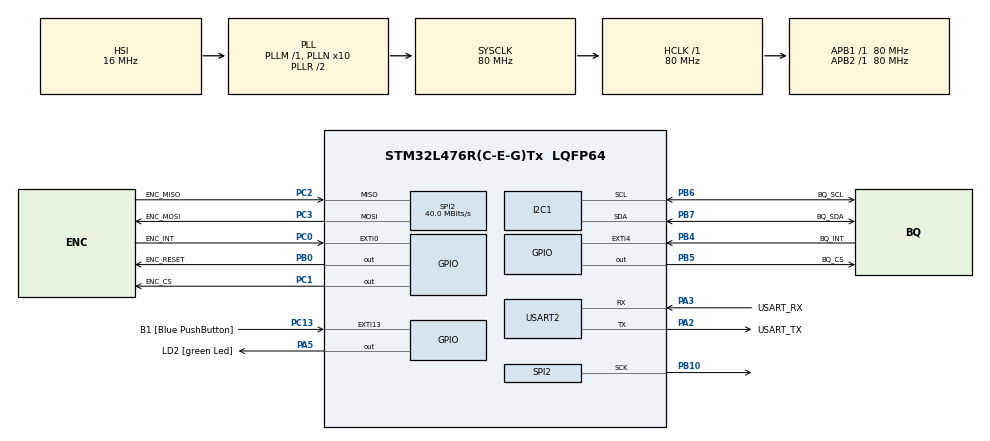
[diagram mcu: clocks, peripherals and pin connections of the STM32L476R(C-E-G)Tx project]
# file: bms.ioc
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FREERTOS.Tasks01=defaultTask,0,128,StartDefaultTask,Default,NULL,Dynamic,NULL,NULL
FREERTOS.configUSE_NEWLIB_REENTRANT=1
I2C1.Timing=0x10909CEC
Mcu.Family=STM32L4
Mcu.Name=STM32L476R(C-E-G)Tx
Mcu.Package=LQFP64
NVIC.EXTI0_IRQn=true\:5\:0\:false\:false\:true\:true\:true\:true\:true
NVIC.EXTI4_IRQn=true\:5\:0\:false\:false\:true\:true\:true\:true\:true
NVIC.PriorityGroup=NVIC_PRIORITYGROUP_4
NVIC.TIM1_UP_TIM16_IRQn=true\:15\:0\:false\:false\:true\:false\:false\:true\:true
NVIC.TimeBase=TIM1_UP_TIM16_IRQn
NVIC.TimeBaseIP=TIM1
PA13\ (JTMS-SWDIO).GPIO_Label=TMS
PA13\ (JTMS-SWDIO).Mode=Serial_Wire
PA13\ (JTMS-SWDIO).Signal=SYS_JTMS-SWDIO
PA14\ (JTCK-SWCLK).GPIO_Label=TCK
PA14\ (JTCK-SWCLK).Mode=Serial_Wire
PA14\ (JTCK-SWCLK).Signal=SYS_JTCK-SWCLK
PA2.GPIO_Label=USART_TX
PA2.GPIO_Mode=GPIO_MODE_AF_PP
PA2.GPIO_PuPd=GPIO_NOPULL
PA2.GPIO_Speed=GPIO_SPEED_FREQ_VERY_HIGH
PA2.Mode=Asynchronous
PA2.Signal=USART2_TX
PA3.GPIO_Label=USART_RX
PA3.GPIO_Mode=GPIO_MODE_AF_PP
PA3.GPIO_PuPd=GPIO_NOPULL
PA3.GPIO_Speed=GPIO_SPEED_FREQ_VERY_HIGH
PA3.Mode=Asynchronous
PA3.Signal=USART2_RX
PA5.GPIO_Label=LD2 [green Led]
PA5.GPIO_ModeDefaultOutputPP=GPIO_MODE_OUTPUT_PP
PA5.GPIO_PuPd=GPIO_NOPULL
PA5.GPIO_Speed=GPIO_SPEED_FREQ_LOW
PA5.Signal=GPIO_Output
PB0.GPIO_Label=ENC_RESET
PB0.GPIO_Speed=GPIO_SPEED_FREQ_VERY_HIGH
PB0.PinState=GPIO_PIN_SET
PB0.Signal=GPIO_Output
PB10.Mode=Full_Duplex_Master
PB10.Signal=SPI2_SCK
PB3\ (JTDO-TRACESWO).GPIO_Label=SWO
PB3\ (JTDO-TRACESWO).Signal=SYS_JTDO-SWO
PB4\ (NJTRST).GPIO_Label=BQ_INT
PB4\ (NJTRST).GPIO_ModeDefaultEXTI=GPIO_MODE_IT_FALLING
PB4\ (NJTRST).Signal=GPXTI4
PB5.GPIO_Label=BQ_CS
PB5.GPIO_Speed=GPIO_SPEED_FREQ_VERY_HIGH
PB5.PinState=GPIO_PIN_SET
PB5.Signal=GPIO_Output
PB6.GPIO_Label=BQ_SCL
PB6.Mode=I2C
PB6.Signal=I2C1_SCL
PB7.GPIO_Label=BQ_SDA
PB7.Mode=I2C
PB7.Signal=I2C1_SDA
PC0.GPIO_Label=ENC_INT
PC0.GPIO_ModeDefaultEXTI=GPIO_MODE_IT_FALLING
PC0.Signal=GPXTI0
PC1.GPIO_Label=ENC_CS
PC1.GPIO_Speed=GPIO_SPEED_FREQ_VERY_HIGH
PC1.PinState=GPIO_PIN_SET
PC1.Signal=GPIO_Output
PC13.GPIO_Label=B1 [Blue PushButton]
PC13.GPIO_ModeDefaultEXTI=GPIO_MODE_IT_FALLING
PC13.GPIO_PuPd=GPIO_NOPULL
PC13.Signal=GPXTI13
PC14-OSC32_IN\ (PC14).Mode=LSE-External-Oscillator
PC14-OSC32_IN\ (PC14).Signal=RCC_OSC32_IN
PC15-OSC32_OUT\ (PC15).Mode=LSE-External-Oscillator
PC15-OSC32_OUT\ (PC15).Signal=RCC_OSC32_OUT
PC2.GPIO_Label=ENC_MISO
PC2.Mode=Full_Duplex_Master
PC2.Signal=SPI2_MISO
PC3.GPIO_Label=ENC_MOSI
PC3.Mode=Full_Duplex_Master
PC3.Signal=SPI2_MOSI
PH0-OSC_IN\ (PH0).Signal=RCC_OSC_IN
PH1-OSC_OUT\ (PH1).Signal=RCC_OSC_OUT
ProjectManager.HeapSize=0x200
ProjectManager.StackSize=0x400
ProjectManager.TargetToolchain=Makefile
RCC.ADCFreq_Value=64000000
RCC.AHBFreq_Value=80000000
RCC.APB1Freq_Value=80000000
RCC.APB1TimFreq_Value=80000000
RCC.APB2Freq_Value=80000000
RCC.APB2TimFreq_Value=80000000
RCC.CortexFreq_Value=80000000
RCC.HCLKFreq_Value=80000000
RCC.HSE_VALUE=8000000
RCC.HSI_VALUE=16000000
RCC.MSI_VALUE=4000000
RCC.PLLN=10
RCC.PLLSourceVirtual=RCC_PLLSOURCE_HSI
RCC.PREFETCH_ENABLE=1
RCC.SYSCLKFreq_VALUE=80000000
RCC.SYSCLKSource=RCC_SYSCLKSOURCE_PLLCLK
RCC.USBFreq_Value=64000000
RCC.VCOOutputFreq_Value=160000000
SPI2.CalculateBaudRate=40.0 MBits/s
SPI2.DataSize=SPI_DATASIZE_8BIT
SPI2.Direction=SPI_DIRECTION_2LINES
SPI2.Mode=SPI_MODE_MASTER
SPI2.VirtualType=VM_MASTER
USART2.VirtualMode-Asynchronous=VM_ASYNC
VP_FREERTOS_VS_CMSIS_V1.Mode=CMSIS_V1
VP_SYS_VS_tim1.Mode=TIM1
board=NUCLEO-L476RG

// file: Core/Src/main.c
/* USER CODE BEGIN Header */
/**
 ******************************************************************************
 * @file           : main.c
 * @brief          : Main program body
 ******************************************************************************
 * @attention
 *
 * Copyright (c) 2022 STMicroelectronics.
 * All rights reserved.
 *
 * This software is licensed under terms that can be found in the LICENSE file
 * in the root directory of this software component.
 * If no LICENSE file comes with this software, it is provided AS-IS.
 *
 ******************************************************************************
 */
/* USER CODE END Header */
#include "main.h"
#include "bq76940.h"
#include "cmsis_os.h"
#include "echoserver.h"
#include "enc28j60.h"
#include "log.h"

I2C_HandleTypeDef hi2c1;

SPI_HandleTypeDef hspi2;

UART_HandleTypeDef huart2;

// TCP Stack - IP configuration
uint8_t ucMACAddress[6] = {0x00, 0x11, 0x00, 0xdd, 0xee, 0xff};
uint8_t ucIPAddress[4] = {172, 16, 15, 133};
uint8_t ucNetMask[4] = {255, 255, 255, 0};
uint8_t ucGatewayAddress[4] = {172, 16, 15, 1};
// The following is the address of an OpenDNS server.
uint8_t ucDNSServerAddress[4] = {208, 67, 222, 222};

void SystemClock_Config(void);
static void MX_GPIO_Init(void);
static void MX_I2C1_Init(void);
static void MX_SPI2_Init(void);
static void MX_USART2_UART_Init(void);

void bq_test() {
  LogDebug("bq_test started\n");

  BQConfig bq_conf = {.scp_threshold = SCD_T_44mV,
                      .scp_delay = SCD_D_100us,
                      .ocp_threshold = OCD_T_17mV,
                      .ocp_delay = OCD_D_8ms,
                      .uv_threshold = 1.5,
                      .uv_delay = UV_D_1s,
                      .ov_threshold = 4.7,
                      .ov_delay = OV_D_1s,
                      .temp_source = TS_SRC_External};

  while (bq769x0_init(&bq_conf)) {
  }
  LogDebug("bq769x0_init success\n");

  LogDebug("cell3: %f\n", bq769x0_read_cell_voltage(BQ_CELL_3));
  LogDebug("pack: %f\n", bq769x0_read_pack_voltage(13));

  while (true) {
    SYS_STAT_Type data = bq769x0_system_faults();
    LogDebug("cell1: %f\n", bq769x0_read_cell_voltage(BQ_CELL_1));
    LogDebug("faults: %d\n", data.byte);
    bq769x0_system_clear_faults(data);
    vTaskDelay(100);
  }

  LogDebug("bq_test stop\n");
  vTaskDelete(NULL);
}

int main(void) {

  HAL_Init();
  SystemClock_Config();
  MX_GPIO_Init();
  MX_I2C1_Init();
  MX_SPI2_Init();
  MX_USART2_UART_Init();

  xLoggingTaskInitialize(1024, 1, 1024);

  LogDebug("CPU, GPIO initialized\n");

  // FreeRTOS_IPInit(ucIPAddress, ucNetMask, ucGatewayAddress,
  // ucDNSServerAddress,
  //                 ucMACAddress);

  xTaskCreate(bq_test, "bq_test", 1024, NULL, osPriorityNormal, NULL);

  LogDebug("starting scheduler\n");
  vTaskStartScheduler();

  /* We should never get here as control is now taken by the scheduler */
  Error_Handler();
}

void vApplicationIPNetworkEventHook(eIPCallbackEvent_t eNetworkEvent) {
  uint32_t ulIPAddress, ulNetMask, ulGatewayAddress, ulDNSServerAddress;
  static BaseType_t xTasksAlreadyCreated = pdFALSE;
  char cBuffer[16];

  /* Both eNetworkUp and eNetworkDown events can be processed here. */
  if (eNetworkEvent == eNetworkUp) {
    LogInfo("Link Up");
    /* Create the tasks that use the TCP/IP stack if they have not already
    been created. */
    if (xTasksAlreadyCreated == pdFALSE) {
      /* Create the task(s) */

      xTaskCreate(vStartSimpleEchoServer, "echo_server", 1024, NULL,
                  osPriorityNormal, NULL);

      xTasksAlreadyCreated = pdTRUE;
    }
    /* The network is up and configured.  Print out the configuration,
   which may have been obtained from a DHCP server. */
    FreeRTOS_GetAddressConfiguration(&ulIPAddress, &ulNetMask,
                                     &ulGatewayAddress, &ulDNSServerAddress);

    /* Convert the IP address to a string then print it out. */
    FreeRTOS_inet_ntoa(ulIPAddress, cBuffer);
    LogInfo("IP Address: %s", cBuffer);

    /* Convert the net mask to a string then print it out. */
    FreeRTOS_inet_ntoa(ulNetMask, cBuffer);
    LogInfo("Subnet Mask: %s", cBuffer);

    /* Convert the IP address of the gateway to a string then print it out. */
    FreeRTOS_inet_ntoa(ulGatewayAddress, cBuffer);
    LogInfo("Gateway IP Address: %s", cBuffer);

    /* Convert the IP address of the DNS server to a string then print it out.
     */
    FreeRTOS_inet_ntoa(ulDNSServerAddress, cBuffer);
    LogInfo("DNS server IP Address: %s", cBuffer);

    LogInfo("Network interface revision_id %#02x", enc28j60_rcr(EREVID));
    LogInfo("MAC address %02x:%02x:%02x:%02x:%02x:%02x filter: %x\n",
            enc28j60_rcr(MAADR5), enc28j60_rcr(MAADR4), enc28j60_rcr(MAADR3),
            enc28j60_rcr(MAADR2), enc28j60_rcr(MAADR1), enc28j60_rcr(MAADR0),
            enc28j60_rcr(ERXFCON));

  } else {
    LogWarn("Link Down");
  }
}

void SystemClock_Config(void) {
  RCC_OscInitTypeDef RCC_OscInitStruct = {0};
  RCC_ClkInitTypeDef RCC_ClkInitStruct = {0};

  /** Configure the main internal regulator output voltage
   */
  if (HAL_PWREx_ControlVoltageScaling(PWR_REGULATOR_VOLTAGE_SCALE1) != HAL_OK) {
    Error_Handler();
  }

  /** Initializes the RCC Oscillators according to the specified parameters
   * in the RCC_OscInitTypeDef structure.
   */
  RCC_OscInitStruct.OscillatorType = RCC_OSCILLATORTYPE_HSI;
  RCC_OscInitStruct.HSIState = RCC_HSI_ON;
  RCC_OscInitStruct.HSICalibrationValue = RCC_HSICALIBRATION_DEFAULT;
  RCC_OscInitStruct.PLL.PLLState = RCC_PLL_ON;
  RCC_OscInitStruct.PLL.PLLSource = RCC_PLLSOURCE_HSI;
  RCC_OscInitStruct.PLL.PLLM = 1;
  RCC_OscInitStruct.PLL.PLLN = 10;
  RCC_OscInitStruct.PLL.PLLP = RCC_PLLP_DIV7;
  RCC_OscInitStruct.PLL.PLLQ = RCC_PLLQ_DIV2;
  RCC_OscInitStruct.PLL.PLLR = RCC_PLLR_DIV2;
  if (HAL_RCC_OscConfig(&RCC_OscInitStruct) != HAL_OK) {
    Error_Handler();
  }

  /** Initializes the CPU, AHB and APB buses clocks
   */
  RCC_ClkInitStruct.ClockType = RCC_CLOCKTYPE_HCLK | RCC_CLOCKTYPE_SYSCLK |
                                RCC_CLOCKTYPE_PCLK1 | RCC_CLOCKTYPE_PCLK2;
  RCC_ClkInitStruct.SYSCLKSource = RCC_SYSCLKSOURCE_PLLCLK;
  RCC_ClkInitStruct.AHBCLKDivider = RCC_SYSCLK_DIV1;
  RCC_ClkInitStruct.APB1CLKDivider = RCC_HCLK_DIV1;
  RCC_ClkInitStruct.APB2CLKDivider = RCC_HCLK_DIV1;

  if (HAL_RCC_ClockConfig(&RCC_ClkInitStruct, FLASH_LATENCY_4) != HAL_OK) {
    Error_Handler();
  }
}

static void MX_I2C1_Init(void) {

  hi2c1.Instance = I2C1;
  hi2c1.Init.Timing = 0x10909CEC;
  hi2c1.Init.OwnAddress1 = 0;
  hi2c1.Init.AddressingMode = I2C_ADDRESSINGMODE_7BIT;
  hi2c1.Init.DualAddressMode = I2C_DUALADDRESS_DISABLE;
  hi2c1.Init.OwnAddress2 = 0;
  hi2c1.Init.OwnAddress2Masks = I2C_OA2_NOMASK;
  hi2c1.Init.GeneralCallMode = I2C_GENERALCALL_DISABLE;
  hi2c1.Init.NoStretchMode = I2C_NOSTRETCH_DISABLE;
  if (HAL_I2C_Init(&hi2c1) != HAL_OK) {
    Error_Handler();
  }

  /** Configure Analogue filter
   */
  if (HAL_I2CEx_ConfigAnalogFilter(&hi2c1, I2C_ANALOGFILTER_ENABLE) != HAL_OK) {
    Error_Handler();
  }

  /** Configure Digital filter
   */
  if (HAL_I2CEx_ConfigDigitalFilter(&hi2c1, 0) != HAL_OK) {
    Error_Handler();
  }
}

static void MX_SPI2_Init(void) {

  /* SPI2 parameter configuration*/
  hspi2.Instance = SPI2;
  hspi2.Init.Mode = SPI_MODE_MASTER;
  hspi2.Init.Direction = SPI_DIRECTION_2LINES;
  hspi2.Init.DataSize = SPI_DATASIZE_8BIT;
  hspi2.Init.CLKPolarity = SPI_POLARITY_LOW;
  hspi2.Init.CLKPhase = SPI_PHASE_1EDGE;
  hspi2.Init.NSS = SPI_NSS_SOFT;
  hspi2.Init.BaudRatePrescaler = SPI_BAUDRATEPRESCALER_2;
  hspi2.Init.FirstBit = SPI_FIRSTBIT_MSB;
  hspi2.Init.TIMode = SPI_TIMODE_DISABLE;
  hspi2.Init.CRCCalculation = SPI_CRCCALCULATION_DISABLE;
  hspi2.Init.CRCPolynomial = 7;
  hspi2.Init.CRCLength = SPI_CRC_LENGTH_DATASIZE;
  hspi2.Init.NSSPMode = SPI_NSS_PULSE_ENABLE;
  if (HAL_SPI_Init(&hspi2) != HAL_OK) {
    Error_Handler();
  }
}

static void MX_USART2_UART_Init(void) {

  huart2.Instance = USART2;
  huart2.Init.BaudRate = 115200;
  huart2.Init.WordLength = UART_WORDLENGTH_8B;
  huart2.Init.StopBits = UART_STOPBITS_1;
  huart2.Init.Parity = UART_PARITY_NONE;
  huart2.Init.Mode = UART_MODE_TX_RX;
  huart2.Init.HwFlowCtl = UART_HWCONTROL_NONE;
  huart2.Init.OverSampling = UART_OVERSAMPLING_16;
  huart2.Init.OneBitSampling = UART_ONE_BIT_SAMPLE_DISABLE;
  huart2.AdvancedInit.AdvFeatureInit = UART_ADVFEATURE_NO_INIT;
  if (HAL_UART_Init(&huart2) != HAL_OK) {
    Error_Handler();
  }
}

static void MX_GPIO_Init(void) {
  GPIO_InitTypeDef GPIO_InitStruct = {0};

  /* GPIO Ports Clock Enable */
  __HAL_RCC_GPIOC_CLK_ENABLE();
  __HAL_RCC_GPIOH_CLK_ENABLE();
  __HAL_RCC_GPIOA_CLK_ENABLE();
  __HAL_RCC_GPIOB_CLK_ENABLE();

  /*Configure GPIO pin Output Level */
  HAL_GPIO_WritePin(ENC_CS_GPIO_Port, ENC_CS_Pin, GPIO_PIN_SET);

  /*Configure GPIO pin Output Level */
  HAL_GPIO_WritePin(LD2_GPIO_Port, LD2_Pin, GPIO_PIN_RESET);

  /*Configure GPIO pin Output Level */
  HAL_GPIO_WritePin(GPIOB, ENC_RESET_Pin | BQ_CS_Pin, GPIO_PIN_SET);

  /*Configure GPIO pins : B1_Pin ENC_INT_Pin */
  GPIO_InitStruct.Pin = B1_Pin | ENC_INT_Pin;
  GPIO_InitStruct.Mode = GPIO_MODE_IT_FALLING;
  GPIO_InitStruct.Pull = GPIO_NOPULL;
  HAL_GPIO_Init(GPIOC, &GPIO_InitStruct);

  /*Configure GPIO pin : ENC_CS_Pin */
  GPIO_InitStruct.Pin = ENC_CS_Pin;
  GPIO_InitStruct.Mode = GPIO_MODE_OUTPUT_PP;
  GPIO_InitStruct.Pull = GPIO_NOPULL;
  GPIO_InitStruct.Speed = GPIO_SPEED_FREQ_VERY_HIGH;
  HAL_GPIO_Init(ENC_CS_GPIO_Port, &GPIO_InitStruct);

  /*Configure GPIO pin : LD2_Pin */
  GPIO_InitStruct.Pin = LD2_Pin;
  GPIO_InitStruct.Mode = GPIO_MODE_OUTPUT_PP;
  GPIO_InitStruct.Pull = GPIO_NOPULL;
  GPIO_InitStruct.Speed = GPIO_SPEED_FREQ_LOW;
  HAL_GPIO_Init(LD2_GPIO_Port, &GPIO_InitStruct);

  /*Configure GPIO pins : ENC_RESET_Pin BQ_CS_Pin */
  GPIO_InitStruct.Pin = ENC_RESET_Pin | BQ_CS_Pin;
  GPIO_InitStruct.Mode = GPIO_MODE_OUTPUT_PP;
  GPIO_InitStruct.Pull = GPIO_NOPULL;
  GPIO_InitStruct.Speed = GPIO_SPEED_FREQ_VERY_HIGH;
  HAL_GPIO_Init(GPIOB, &GPIO_InitStruct);

  /*Configure GPIO pin : BQ_INT_Pin */
  GPIO_InitStruct.Pin = BQ_INT_Pin;
  GPIO_InitStruct.Mode = GPIO_MODE_IT_FALLING;
  GPIO_InitStruct.Pull = GPIO_NOPULL;
  HAL_GPIO_Init(BQ_INT_GPIO_Port, &GPIO_InitStruct);

  /* EXTI interrupt init*/
  HAL_NVIC_SetPriority(EXTI0_IRQn, 13, 13);
  HAL_NVIC_EnableIRQ(EXTI0_IRQn);

  // HAL_NVIC_SetPriority(EXTI4_IRQn, 13, 13);
  // HAL_NVIC_EnableIRQ(EXTI4_IRQn);
}

void HAL_TIM_PeriodElapsedCallback(TIM_HandleTypeDef *htim) {
  if (htim->Instance == TIM1) {
    HAL_IncTick();
  }
}

void HAL_GPIO_EXTI_Callback(uint16_t GPIO_Pin) {
  // This function is called for every EXTI event so
  // we need first to sort out which pin sourced it
  if (GPIO_Pin == ENC_INT_Pin) {
    ENC_IRQHandler();
  }
}

void Error_Handler(void) {
  /* USER CODE BEGIN Error_Handler_Debug */
  printf("This function is executed in case of error occurrence\n");
  /* User can add his own implementation to report the HAL error return state */
  __disable_irq();
  while (1) {
  }
  /* USER CODE END Error_Handler_Debug */
}

#ifdef USE_FULL_ASSERT
/**
 * @brief  Reports the name of the source file and the source line number
 *         where the assert_param error has occurred.
 * @param  file: pointer to the source file name
 * @param  line: assert_param error line source number
 * @retval None
 */
void assert_failed(uint8_t *file, uint32_t line) {
  /* USER CODE BEGIN 6 */
  /* User can add his own implementation to report the file name and line
     number, ex: printf("Wrong parameters value: file %s on line %d\r\n", file,
     line) */
  /* USER CODE END 6 */
}
#endif /* USE_FULL_ASSERT */
